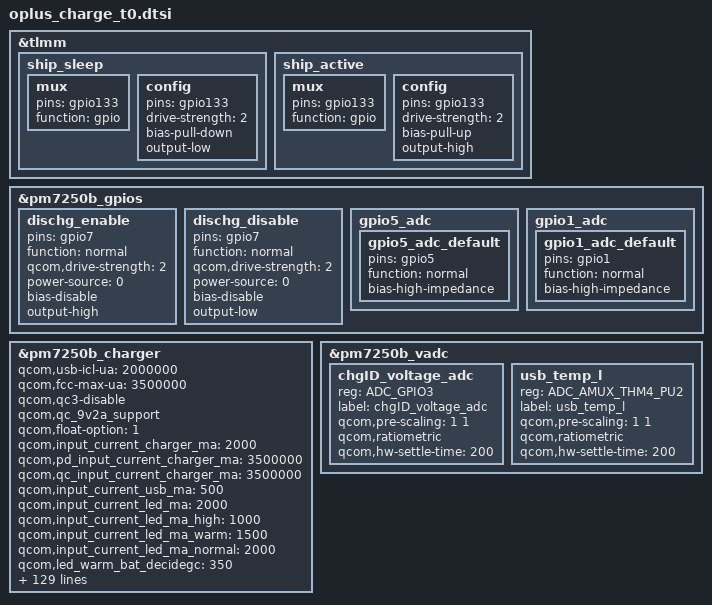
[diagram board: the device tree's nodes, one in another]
// SPDX-License-Identifier: GPL-2.0-only
/*
 * Copyright (C) 2018-2020 Oplus. All rights reserved.
 */

&tlmm {
			ship_sleep: ship_sleep {
				mux {
					pins = "gpio133";
					function = "gpio";
				};

				config {
					pins = "gpio133";
					drive-strength = <2>;
					bias-pull-down;
					output-low;
				};
			};

			ship_active: ship_active {
				mux {
					pins = "gpio133";
					function = "gpio";
				};

				config {
					pins = "gpio133";
					drive-strength = <2>;
					bias-pull-up;
					output-high;
				};
			};

};

&pm7250b_gpios {
	dischg_enable: dischg_enable{
		pins = "gpio7";
		function = "normal";
		qcom,drive-strength = <2>;
		power-source = <0>;
		bias-disable;
		output-high;
	};

	dischg_disable: dischg_disable{
		pins = "gpio7";
		function = "normal";
		qcom,drive-strength = <2>;
		power-source = <0>;
		bias-disable;
		output-low;
	};

    gpio5_adc {
        gpio5_adc_default: gpio5_adc_default {
        pins = "gpio5"; /* GPIO 7 */
        function = "normal"; /* normal */
        bias-high-impedance; /* DISABLE GPIO7 for ADC*/
        };
    };    
	gpio1_adc {
        gpio1_adc_default: gpio1_adc_default {
        pins = "gpio1"; /* GPIO 1 */
        function = "normal"; /* normal */
        bias-high-impedance; /* DISABLE GPIO1 for ADC*/
        };
    };
};

&pm7250b_charger {
			//test_bob-supply = <&pm8150a_bob>;
			qcom,usb-icl-ua = <2000000>;
			qcom,fcc-max-ua = <3500000>;
			//qcom,fv-max-uv = <4373000>;
			qcom,qc3-disable;
			//qcom,hvdcp-disable;
			qcom,qc_9v2a_support;
			
			//io-channels = <&pm8150b_vadc ADC_GPIO3>;
			//io-channel-names = "chgID_voltage_adc";
			//qcom,otg-cl-ua = <2000000>;
			qcom,float-option = <1>;

			//for oplus chg framework:
			qcom,input_current_charger_ma = <2000>;
			qcom,pd_input_current_charger_ma = <3500000>;
			qcom,qc_input_current_charger_ma = <3500000>;
			qcom,input_current_usb_ma = <500>;

			qcom,input_current_led_ma = <2000>;
			qcom,input_current_led_ma_high = <1000>;
			qcom,input_current_led_ma_warm = <1500>;
			qcom,input_current_led_ma_normal = <2000>;
			qcom,led_warm_bat_decidegc = <350>;
			qcom,led_high_bat_decidegc = <370>;

			qcom,input_current_camera_ma = <1200>;
			qcom,input_current_cdp_ma = <1500>;

			qcom,input_current_vooc_led_ma_high = <1200>;
			qcom,input_current_vooc_led_ma_warm = <1800>;
			qcom,input_current_vooc_led_ma_normal = <3600>;
			qcom,input_current_vooc_ma_normal = <3600>;
			qcom,vooc_temp_bat_normal_decidegc = <340>;
			qcom,input_current_vooc_ma_warm = <3200>;
			qcom,vooc_temp_bat_warm_decidegc = <360>;
			qcom,input_current_vooc_ma_high = <2200>;
			qcom,vooc_temp_bat_hot_decidegc = <440>;

			qcom,charger_current_vooc_ma_normal = <1800>;

			qcom,chg_ctrl_by_calling;
			qcom,input_current_calling_ma = <1500>;

			//qcom,input_current_led_ma_overtemp = <900>;
			qcom,overtemp_bat_decidegc = <350>;
			qcom,iterm_disabled = <0>;
			sw_full_count = <25>;
			qcom,iterm_ma = <108>;
			qcom,recharge-mv = <100>;
			qcom,batt_capacity_mah = <4000>;/*typical capacity*/
			//qcom,batt_capacity_mah = <3950>; /*rated capacity*/

			qcom,removed_bat_decidegc = <190>;  /*<-19C*/

			qcom,cold_bat_decidegc = <20>;  /*-2C~0C*/
			qcom,temp_cold_vfloat_mv = <3980>;
			qcom,temp_cold_fastchg_current_ma = <300>;

			qcom,little_cold_bat_decidegc = <0>;	/*0C~5C*/
			qcom,temp_little_cold_vfloat_mv = <4435>;
			qcom,temp_little_cold_fastchg_current_ma_high = <920>;
			qcom,temp_little_cold_fastchg_current_ma_low = <920>;
			qcom,temp_little_cold_fastchg_current_ma = <920>;
			qcom,pd_temp_little_cold_fastchg_current_ma_high = <2000>;
			qcom,pd_temp_little_cold_fastchg_current_ma_low = <1350>;
			qcom,qc_temp_little_cold_fastchg_current_ma_high = <2000>;
			qcom,qc_temp_little_cold_fastchg_current_ma_low = <1350>;

			qcom,cool_bat_decidegc = <50>;	/*5C~12C*/
			qcom,temp_cool_vfloat_mv = <4435>;
			qcom,temp_cool_fastchg_current_ma_high = <1100>;
			qcom,temp_cool_fastchg_current_ma_low = <1100>;
			qcom,pd_temp_cool_fastchg_current_ma_high = <2000>;
			qcom,pd_temp_cool_fastchg_current_ma_low = <1950>;
			qcom,qc_temp_cool_fastchg_current_ma_high = <2000>;
			qcom,qc_temp_cool_fastchg_current_ma_low = <1950>;

			qcom,little_cool_bat_decidegc = <120>;	/*12C~16C*/
			qcom,temp_little_cool_vfloat_mv = <4435>;
			qcom,temp_little_cool_fastchg_current_ma = <1100>;
			qcom,pd_temp_little_cool_fastchg_current_ma = <2000>;
			qcom,qc_temp_little_cool_fastchg_current_ma = <2000>;

			qcom,normal_bat_decidegc = <160>;	/*16C~44C*/
			qcom,temp_normal_fastchg_current_ma = <3500>;
			qcom,temp_normal_vfloat_mv = <4435>;
			qcom,pd_temp_normal_fastchg_current_ma = <3500>;
			qcom,qc_temp_normal_fastchg_current_ma = <3500>;

			qcom,warm_bat_decidegc = <450>;		/*45C~53C*/ /*8pin Bat Vooc project need add 3 degree C*/
			qcom,temp_warm_vfloat_mv = <4130>;
			qcom,temp_warm_fastchg_current_ma = <550>;
			qcom,pd_temp_warm_fastchg_current_ma = <550>;
			qcom,qc_temp_warm_fastchg_current_ma = <550>;
			qcom,temp_warm_fastchg_current_ma_led_on = <250>;

			qcom,hot_bat_decidegc = <530>;

			qcom,non_standard_vfloat_mv = <3980>;
			qcom,non_standard_fastchg_current_ma = <512>;

			qcom,short_c_bat_cv_mv = <4330>;
			qcom,short_c_bat_vfloat_mv = <3800>;
			qcom,short_c_bat_fastchg_current_ma = <512>;

			qcom,cold_vfloat_sw_limit = <3930>;
			qcom,little_cold_vfloat_sw_limit = <4385>;
			qcom,cool_vfloat_sw_limit = <4385>;
			qcom,little_cool_vfloat_sw_limit = <4385>;
			qcom,normal_vfloat_sw_limit = <4385>;
			qcom,warm_vfloat_sw_limit = <4080>;
			qcom,non_standard_vfloat_sw_limit = <3930>;
			qcom,short_c_bat_vfloat_sw_limit = <3750>;

			qcom,max_chg_time_sec = <36000>;
			qcom,charger_hv_thr = <9900>;
			qcom,charger_recv_thr = <9500>;
			qcom,charger_lv_thr = <3400>;
			qcom,vbatt_full_thr = <4435>;
			qcom,vbatt_hv_thr = <4600>;
			qcom,vfloat_step_mv = <8>;
			qcom,non_standard_vfloat_over_sw_limit = <3990>;
			qcom,cold_vfloat_over_sw_limit = <3990>;
			qcom,little_cold_vfloat_over_sw_limit = <4445>;
			qcom,cool_vfloat_over_sw_limit = <4445>;
			qcom,little_cool_vfloat_over_sw_limit = <4445>;
			qcom,normal_vfloat_over_sw_limit = <4445>;
			qcom,warm_vfloat_over_sw_limit = <4140>;

			qcom,vbatt_power_off = <3300>;
			qcom,vbatt_soc_1 = <3310>;
			//qcom,vooc_project = <3>;
			qcom,vbatt_num = <1>;
			qcom,new_ui_warning_support;
			recharge_after_full;

			qcom,normal_vterm_hw_inc = <18>;
			qcom,non_normal_vterm_hw_inc = <18>;
			
			
			qcom,default_iterm_ma = <108>;
			qcom,default_temp_normal_fastchg_current_ma = <3500>;
			qcom,default_normal_vfloat_sw_limit = <4385>;
			qcom,default_temp_normal_vfloat_mv = <4435>;
			qcom,default_normal_vfloat_over_sw_limit = <4445>;

			qcom,default_temp_little_cool_fastchg_current_ma = <1100>;
			qcom,default_little_cool_vfloat_sw_limit = <4385>;
			qcom,default_temp_little_cool_vfloat_mv = <4435>;
			qcom,default_little_cool_vfloat_over_sw_limit = <4445>;
			
			///qcom,offset_temp = <30>;
			//for control:
			//qcom,suspend_after_full;
			qcom,check_batt_full_by_sw;
			//qcom,external_gauge;
			qcom,chg_ctrl_by_lcd;
			//qcom,chg_ctrl_by_vooc;
			qcom,chg_ctrl_by_camera;
			qcom,sw_vfloat_over_protect_enable;
			qcom,lpd-disable;

			//for PD9V or QC9V
			qcom,vbatt_pdqc_to_5v_thr = <4100>;

			//qcom,chargerid_switch-gpio = <&tlmm 4 0x00>;
			qcom,ship-gpio = <&tlmm 133 0x00>;
			//qcom,shortc-gpio = <&tlmm 43 0x00>;
			qcom,dischg-gpio = <&pm7250b_gpios 7 0x00>;

			pinctrl-names = "default",
							"ship_active", "ship_sleep",
							"dischg_enable", "dischg_disable",
							"gpio1_adc_default";

			pinctrl-0 = <&gpio5_adc_default>;
			pinctrl-1 = <&ship_active>;
			pinctrl-2 = <&ship_sleep>;
			pinctrl-3 = <&dischg_enable>;
			pinctrl-4 = <&dischg_disable>;
			pinctrl-5 = <&gpio1_adc_default>;
};

&pm7250b_vadc {
	chgID_voltage_adc {
		reg = <ADC_GPIO3>;
		label = "chgID_voltage_adc";
		qcom,pre-scaling = <1 1>;
		qcom,ratiometric;
		qcom,hw-settle-time = <200>;
	};
	usb_temp_l {
		reg = <ADC_AMUX_THM4_PU2>;
		label = "usb_temp_l";
		qcom,pre-scaling = <1 1>;
		qcom,ratiometric;
		qcom,hw-settle-time = <200>;
	};
};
